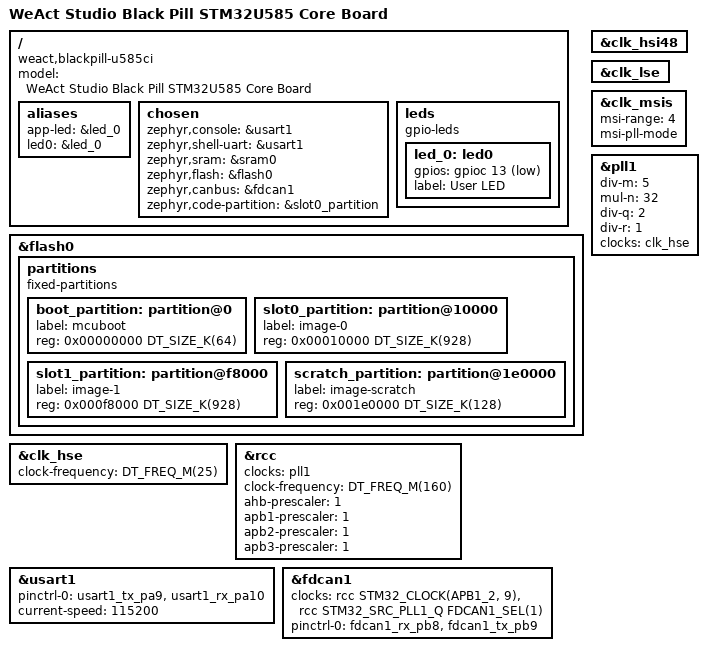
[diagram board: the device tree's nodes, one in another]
/dts-v1/;
#include <st/u5/stm32u585Xi.dtsi>
#include <st/u5/stm32u585ciux-pinctrl.dtsi>
#include <zephyr/dt-bindings/input/input-event-codes.h>

/ {
	model = "WeAct Studio Black Pill STM32U585 Core Board";
	compatible = "weact,blackpill-u585ci";

	aliases {
        app-led=&led_0;
		led0 = &led_0;
    };

    chosen {
		zephyr,console = &usart1;
		zephyr,shell-uart = &usart1;
		zephyr,sram = &sram0;
		zephyr,flash = &flash0;
		zephyr,canbus = &fdcan1;
		zephyr,code-partition = &slot0_partition;
    }; 

	leds {
		compatible = "gpio-leds";

		led_0: led0 {
			gpios = <&gpioc 13 GPIO_ACTIVE_LOW>;
			label = "User LED";
		};
	};   
};

&flash0 {
	partitions {
		compatible = "fixed-partitions";
		#address-cells = <1>;
		#size-cells = <1>;

		boot_partition: partition@0 {
			label = "mcuboot";
			reg = <0x00000000 DT_SIZE_K(64)>;
		};

		slot0_partition: partition@10000 {
			label = "image-0";
			reg = <0x00010000 DT_SIZE_K(928)>;
		};

		slot1_partition: partition@f8000 {
			label = "image-1";
			reg = <0x000f8000 DT_SIZE_K(928)>;
		};

		scratch_partition: partition@1e0000 {
			label = "image-scratch";
			reg = <0x001e0000 DT_SIZE_K(128)>;
		};
	};
};

&clk_hsi48 {
	status = "okay";
};

&clk_lse {
	status = "okay";
};

&clk_hse {
	clock-frequency = <DT_FREQ_M(25)>;
	status = "okay";
};

&clk_msis {
	status = "okay";
	msi-range = <4>;
	msi-pll-mode;
};

&pll1 {
	div-m = <5>;
	mul-n = <32>;
	div-q = <2>;
	div-r = <1>;
	clocks = <&clk_hse>;
	status = "okay";
};


&rcc {
	clocks = <&pll1>;
	clock-frequency = <DT_FREQ_M(160)>;
	ahb-prescaler = <1>;
	apb1-prescaler = <1>;
	apb2-prescaler = <1>;
	apb3-prescaler = <1>;
};

&usart1 {
	pinctrl-0 = <&usart1_tx_pa9 &usart1_rx_pa10>;
	pinctrl-names = "default";
	current-speed = <115200>;
	status = "okay";
};

&fdcan1 {
	clocks = <&rcc STM32_CLOCK(APB1_2, 9)>,
		 <&rcc STM32_SRC_PLL1_Q FDCAN1_SEL(1)>;
	pinctrl-0 = <&fdcan1_rx_pb8 &fdcan1_tx_pb9>;
	pinctrl-names = "default";
	status = "okay";
};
